AUTOSAR XML (schema 4-0-3)
package /ComponentTypes
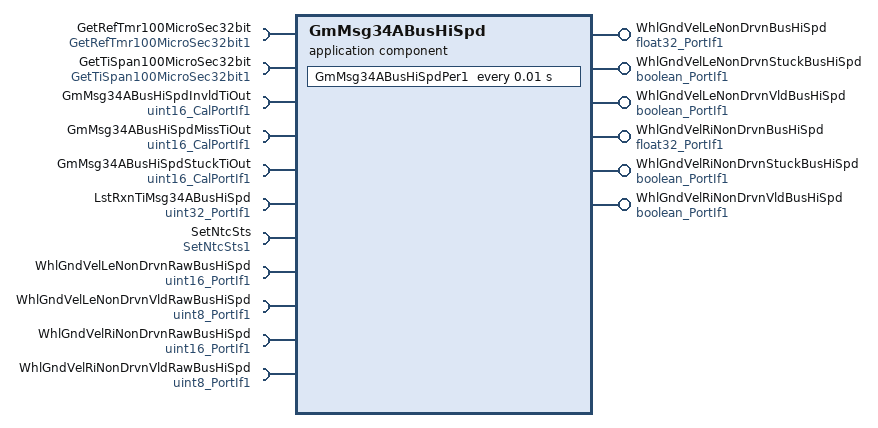
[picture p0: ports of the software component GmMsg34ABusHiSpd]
  application sw component type GmMsg34ABusHiSpd
    6 x provide port:
      WhlGndVelLeNonDrvnBusHiSpd: nonqueued-sender-com-spec{data-element=Val, init-value=0}, provided-interface=float32_PortIf1
      WhlGndVelLeNonDrvnStuckBusHiSpd: nonqueued-sender-com-spec{data-element=Logl, init-value=0}, provided-interface=boolean_PortIf1
      WhlGndVelLeNonDrvnVldBusHiSpd: nonqueued-sender-com-spec{data-element=Logl, init-value=0}, provided-interface=boolean_PortIf1
      WhlGndVelRiNonDrvnBusHiSpd: nonqueued-sender-com-spec{data-element=Val, init-value=0}, provided-interface=float32_PortIf1
      WhlGndVelRiNonDrvnStuckBusHiSpd: nonqueued-sender-com-spec{data-element=Logl, init-value=0}, provided-interface=boolean_PortIf1
      WhlGndVelRiNonDrvnVldBusHiSpd: nonqueued-sender-com-spec{data-element=Logl, init-value=0}, provided-interface=boolean_PortIf1
    11 x require port:
      GetRefTmr100MicroSec32bit: required-interface=GetRefTmr100MicroSec32bit1
      GetTiSpan100MicroSec32bit: required-interface=GetTiSpan100MicroSec32bit1
      GmMsg34ABusHiSpdInvldTiOut: parameter-require-com-spec{init-value=1000, parameter=Val}, required-interface=uint16_CalPortIf1
      GmMsg34ABusHiSpdMissTiOut: parameter-require-com-spec{init-value=500, parameter=Val}, required-interface=uint16_CalPortIf1
      GmMsg34ABusHiSpdStuckTiOut: parameter-require-com-spec{init-value=500, parameter=Val}, required-interface=uint16_CalPortIf1
      LstRxnTiMsg34ABusHiSpd: nonqueued-receiver-com-spec{data-element=Val, filter=data-filter-type=ALWAYS, init-value=0}, required-interface=uint32_PortIf1
      SetNtcSts: required-interface=SetNtcSts1
      WhlGndVelLeNonDrvnRawBusHiSpd: nonqueued-receiver-com-spec{data-element=Val, filter=data-filter-type=ALWAYS, init-value=0}, required-interface=uint16_PortIf1
      WhlGndVelLeNonDrvnVldRawBusHiSpd: nonqueued-receiver-com-spec{data-element=Val, filter=data-filter-type=ALWAYS, init-value=0}, required-interface=uint8_PortIf1
      WhlGndVelRiNonDrvnRawBusHiSpd: nonqueued-receiver-com-spec{data-element=Val, filter=data-filter-type=ALWAYS, init-value=0}, required-interface=uint16_PortIf1
      WhlGndVelRiNonDrvnVldRawBusHiSpd: nonqueued-receiver-com-spec{data-element=Val, filter=data-filter-type=ALWAYS, init-value=0}, required-interface=uint8_PortIf1
    behavior GmMsg34ABusHiSpd_InternalBehavior: data-type-mapping=Nexteer
      ar-typed-per-instance-memorys:
        6 x data, all with sw-calibration-access=READ-ONLY:
          GmMsg34ABusHiSpdPrevWhlGndVelLeNonDrvn: type=uint16
          GmMsg34ABusHiSpdPrevWhlGndVelRiNonDrvn: type=uint16
          GmMsg34ABusHiSpdWhlGndVelLeNonDrvnInvldTi: type=uint32
          GmMsg34ABusHiSpdWhlGndVelLeNonDrvnStuckTi: type=uint32
          GmMsg34ABusHiSpdWhlGndVelRiNonDrvnInvldTi: type=uint32
          GmMsg34ABusHiSpdWhlGndVelRiNonDrvnStuckTi: type=uint32
      timing event TMT_GM0C9HSPer1: start-on-event=GmMsg34ABusHiSpdPer1, period=0.01
      runnable GmMsg34ABusHiSpdPer1
        data-receive-point-by-arguments:
          5 x access:
            REC_HiSpdWhlGndVelLeDrvn_Val: accessed-variable=WhlGndVelLeNonDrvnRawBusHiSpd.Val
            REC_HiSpdWhlGndVelLeDrvnVld_Val: accessed-variable=WhlGndVelLeNonDrvnVldRawBusHiSpd.Val
            REC_HiSpdWhlGndVelRiDrvn_Val: accessed-variable=WhlGndVelRiNonDrvnRawBusHiSpd.Val
            REC_HiSpdWhlGndVelRiDrvnVld_Val: accessed-variable=WhlGndVelRiNonDrvnVldRawBusHiSpd.Val
            REC_Msg348HSLstRxnTi_Val: accessed-variable=LstRxnTiMsg34ABusHiSpd.Val
        data-send-points:
          6 x access:
            SEND_GM348HSWhlGndVelLeDrvn_Val: accessed-variable=WhlGndVelLeNonDrvnBusHiSpd.Val
            SEND_GM348HSWhlGndVelLeDrvnVld_Logl: accessed-variable=WhlGndVelLeNonDrvnVldBusHiSpd.Logl
            SEND_GM348HSWhlGndVelRiDrvn_Val: accessed-variable=WhlGndVelRiNonDrvnBusHiSpd.Val
            SEND_GM348HSWhlGndVelRiDrvnVld_Logl: accessed-variable=WhlGndVelRiNonDrvnVldBusHiSpd.Logl
            SEND_WhlGndVelLeNonDrvnStuckBusHiSpd_Logl: accessed-variable=WhlGndVelLeNonDrvnStuckBusHiSpd.Logl
            SEND_WhlGndVelRiNonDrvnStuckBusHiSpd_Logl: accessed-variable=WhlGndVelRiNonDrvnStuckBusHiSpd.Logl
        sync call SC_GetRefTmr100MicroSec32bit_Oper: operation=GetRefTmr100MicroSec32bit.Oper, timeout=0
        sync call SC_GetTiSpan100MicroSec32bit_Oper: operation=GetTiSpan100MicroSec32bit.Oper, timeout=0
        sync call SC_SetNtcSts_Oper: operation=SetNtcSts.Oper, timeout=0
  swc implementation GmMsg34ABusHiSpd_Implementation: behavior=GmMsg34ABusHiSpd_InternalBehavior
    code-descriptors:
      code Default: artifact-descriptors=autosar-engineering-object={short-label=Default, category=SWSRC}
